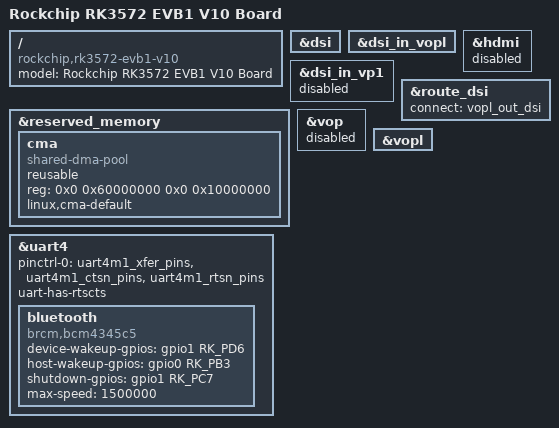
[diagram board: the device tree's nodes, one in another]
// SPDX-License-Identifier: (GPL-2.0+ OR MIT)
/*
 * Copyright (c) 2025 Rockchip Electronics Co., Ltd.
 */

/dts-v1/;

#include "rk3572-evb1-v10.dtsi"
#include "rk3572-linux.dtsi"
#include "rk3572-evb1-cam-csi0.dtsi"

/ {
	model = "Rockchip RK3572 EVB1 V10 Board";
	compatible = "rockchip,rk3572-evb1-v10", "rockchip,rk3572";
};

&dsi {
	status = "okay";
};

&dsi_in_vopl {
	status = "okay";
};

&dsi_in_vp1 {
	status = "disabled";
};

&hdmi {
	status = "disabled";
};

&reserved_memory {
	cma {
		compatible = "shared-dma-pool";
		reusable;
		reg = <0x0 0x60000000 0x0 0x10000000>; //1.5G ~ 1.5G+256MB
		linux,cma-default;
	};
};

&route_dsi {
	status = "okay";
	connect = <&vopl_out_dsi>;
};

&uart4 {
	status = "okay";
	pinctrl-names = "default";
	pinctrl-0 = <&uart4m1_xfer_pins &uart4m1_ctsn_pins &uart4m1_rtsn_pins>;
	uart-has-rtscts;

	bluetooth {
		compatible = "brcm,bcm4345c5";

		device-wakeup-gpios = <&gpio1 RK_PD6 GPIO_ACTIVE_HIGH>;
		host-wakeup-gpios = <&gpio0 RK_PB3 GPIO_ACTIVE_HIGH>;
		shutdown-gpios = <&gpio1 RK_PC7 GPIO_ACTIVE_HIGH>;
		max-speed = <1500000>;
	};
};

&vop {
	status = "disabled";
};

&vopl {
	status = "okay";
};

/delete-node/ &wireless_bluetooth;
